AUTOSAR XML (schema 4-2-2)
package /UAES/ASW
  swc implementation Implementation: programming-language=C, sw-version=1.63.1, used-code-generator=Embedded Coder 7.1 (R2018b) 24-May-2018, vendor-id=0, behavior=InternalBehavior
    code-descriptors:
      code Code
        artifact-descriptors:
          short-label=SlpWkpReq_Ctrl_c, category=SWSRC
          short-label=APP_CFG_h, category=SWHDR
          short-label=ModeM_h, category=SWHDR
          short-label=SlpWkpReq_Ctrl_h, category=SWHDR
          short-label=rtwtypes_h, category=SWHDR
    resource consumption RsrcCons_SlpWkpReq_Ctrl
package /UAES/ASW/SwComponentTypes
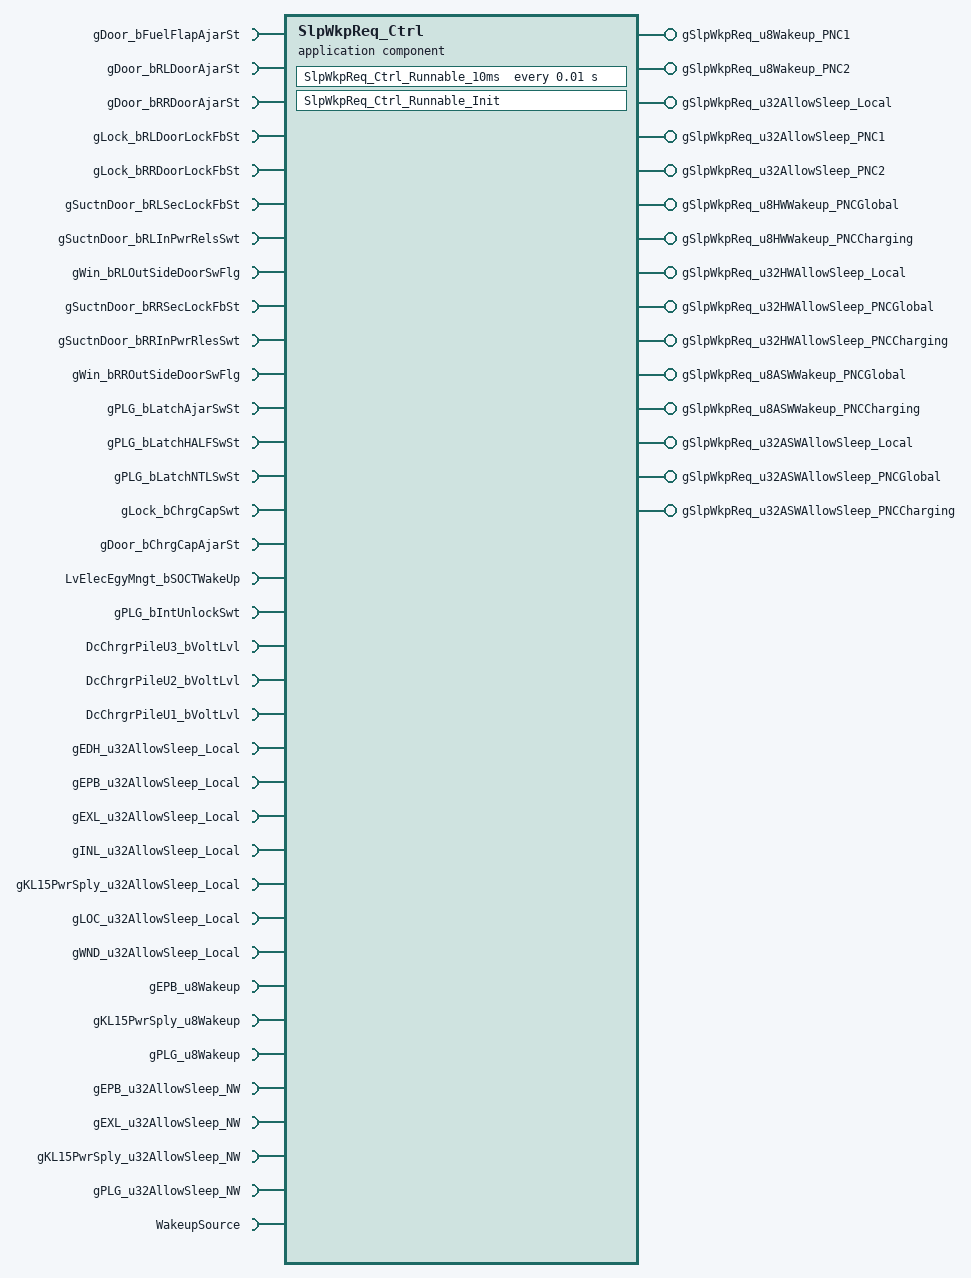
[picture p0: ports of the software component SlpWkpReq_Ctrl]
  application sw component type SlpWkpReq_Ctrl
    35 x require port:
      gDoor_bFuelFlapAjarSt: nonqueued-receiver-com-spec{data-element=gDoor_bFuelFlapAjarSt/Val, init-value=0}, required-interface=gDoor_bFuelFlapAjarSt
      gDoor_bRLDoorAjarSt: nonqueued-receiver-com-spec{data-element=gDoor_bRLDoorAjarSt/Val, init-value=0}, required-interface=gDoor_bRLDoorAjarSt
      gDoor_bRRDoorAjarSt: nonqueued-receiver-com-spec{data-element=gDoor_bRRDoorAjarSt/Val, init-value=0}, required-interface=gDoor_bRRDoorAjarSt
      gLock_bRLDoorLockFbSt: nonqueued-receiver-com-spec{data-element=gLock_bRLDoorLockFbSt/Val, init-value=0}, required-interface=gLock_bRLDoorLockFbSt
      gLock_bRRDoorLockFbSt: nonqueued-receiver-com-spec{data-element=gLock_bRRDoorLockFbSt/Val, init-value=0}, required-interface=gLock_bRRDoorLockFbSt
      gSuctnDoor_bRLSecLockFbSt: nonqueued-receiver-com-spec{data-element=gSuctnDoor_bRLSecLockFbSt/Val, init-value=0}, required-interface=gSuctnDoor_bRLSecLockFbSt
      gSuctnDoor_bRLInPwrRelsSwt: nonqueued-receiver-com-spec{data-element=gSuctnDoor_bRLInPwrRelsSwt/Val, init-value=0}, required-interface=gSuctnDoor_bRLInPwrRelsSwt
      gWin_bRLOutSideDoorSwFlg: nonqueued-receiver-com-spec{data-element=gWin_bRLOutSideDoorSwFlg/Val, init-value=0}, required-interface=gWin_bRLOutSideDoorSwFlg
      gSuctnDoor_bRRSecLockFbSt: nonqueued-receiver-com-spec{data-element=gSuctnDoor_bRRSecLockFbSt/Val, init-value=0}, required-interface=gSuctnDoor_bRRSecLockFbSt
      gSuctnDoor_bRRInPwrRlesSwt: nonqueued-receiver-com-spec{data-element=gSuctnDoor_bRRInPwrRlesSwt/Val, init-value=0}, required-interface=gSuctnDoor_bRRInPwrRlesSwt
      gWin_bRROutSideDoorSwFlg: nonqueued-receiver-com-spec{data-element=gWin_bRROutSideDoorSwFlg/Val, init-value=0}, required-interface=gWin_bRROutSideDoorSwFlg
      gPLG_bLatchAjarSwSt: nonqueued-receiver-com-spec{data-element=gPLG_bLatchAjarSwSt/Val, init-value=0}, required-interface=gPLG_bLatchAjarSwSt
      gPLG_bLatchHALFSwSt: nonqueued-receiver-com-spec{data-element=gPLG_bLatchHALFSwSt/Val, init-value=0}, required-interface=gPLG_bLatchHALFSwSt
      gPLG_bLatchNTLSwSt: nonqueued-receiver-com-spec{data-element=gPLG_bLatchNTLSwSt/Val, init-value=0}, required-interface=gPLG_bLatchNTLSwSt
      gLock_bChrgCapSwt: nonqueued-receiver-com-spec{data-element=gLock_bChrgCapSwt/Val, init-value=0}, required-interface=gLock_bChrgCapSwt
      gDoor_bChrgCapAjarSt: nonqueued-receiver-com-spec{data-element=gDoor_bChrgCapAjarSt/Val, init-value=0}, required-interface=gDoor_bChrgCapAjarSt
      LvElecEgyMngt_bSOCTWakeUp: nonqueued-receiver-com-spec{data-element=LvElecEgyMngt_bSOCTWakeUp/Val, init-value=0}, required-interface=LvElecEgyMngt_bSOCTWakeUp
      gPLG_bIntUnlockSwt: nonqueued-receiver-com-spec{data-element=gPLG_bIntUnlockSwt/Val, init-value=0}, required-interface=gPLG_bIntUnlockSwt
      DcChrgrPileU3_bVoltLvl: nonqueued-receiver-com-spec{data-element=DcChrgrPileU3_bVoltLvl/Val, init-value=0}, required-interface=DcChrgrPileU3_bVoltLvl
      DcChrgrPileU2_bVoltLvl: nonqueued-receiver-com-spec{data-element=DcChrgrPileU2_bVoltLvl/Val, init-value=0}, required-interface=DcChrgrPileU2_bVoltLvl
      DcChrgrPileU1_bVoltLvl: nonqueued-receiver-com-spec{data-element=DcChrgrPileU1_bVoltLvl/Val, init-value=0}, required-interface=DcChrgrPileU1_bVoltLvl
      gEDH_u32AllowSleep_Local: nonqueued-receiver-com-spec{data-element=gEDH_u32AllowSleep_Local/Val, init-value=0}, required-interface=gEDH_u32AllowSleep_Local
      gEPB_u32AllowSleep_Local: nonqueued-receiver-com-spec{data-element=gEPB_u32AllowSleep_Local/Val, init-value=0}, required-interface=gEPB_u32AllowSleep_Local
      gEXL_u32AllowSleep_Local: nonqueued-receiver-com-spec{data-element=gEXL_u32AllowSleep_Local/Val, init-value=0}, required-interface=gEXL_u32AllowSleep_Local
      gINL_u32AllowSleep_Local: nonqueued-receiver-com-spec{data-element=gINL_u32AllowSleep_Local/Val, init-value=0}, required-interface=gINL_u32AllowSleep_Local
      gKL15PwrSply_u32AllowSleep_Local: nonqueued-receiver-com-spec{data-element=gKL15PwrSply_u32AllowSleep_Local/Val, init-value=0}, required-interface=gKL15PwrSply_u32AllowSleep_Local
      gLOC_u32AllowSleep_Local: nonqueued-receiver-com-spec{data-element=gLOC_u32AllowSleep_Local/Val, init-value=0}, required-interface=gLOC_u32AllowSleep_Local
      gWND_u32AllowSleep_Local: nonqueued-receiver-com-spec{data-element=gWND_u32AllowSleep_Local/Val, init-value=0}, required-interface=gWND_u32AllowSleep_Local
      gEPB_u8Wakeup: nonqueued-receiver-com-spec{data-element=gEPB_u8Wakeup/Val, init-value=0}, required-interface=gEPB_u8Wakeup
      gKL15PwrSply_u8Wakeup: nonqueued-receiver-com-spec{data-element=gKL15PwrSply_u8Wakeup/Val, init-value=0}, required-interface=gKL15PwrSply_u8Wakeup
      gPLG_u8Wakeup: nonqueued-receiver-com-spec{data-element=gPLG_u8Wakeup/Val, init-value=0}, required-interface=gPLG_u8Wakeup
      gEPB_u32AllowSleep_NW: nonqueued-receiver-com-spec{data-element=gEPB_u32AllowSleep_NW/Val, init-value=0}, required-interface=gEPB_u32AllowSleep_NW
      gEXL_u32AllowSleep_NW: nonqueued-receiver-com-spec{data-element=gEXL_u32AllowSleep_NW/Val, init-value=0}, required-interface=gEXL_u32AllowSleep_NW
      gKL15PwrSply_u32AllowSleep_NW: nonqueued-receiver-com-spec{data-element=gKL15PwrSply_u32AllowSleep_NW/Val, init-value=0}, required-interface=gKL15PwrSply_u32AllowSleep_NW
      gPLG_u32AllowSleep_NW: nonqueued-receiver-com-spec{data-element=gPLG_u32AllowSleep_NW/Val, init-value=0}, required-interface=gPLG_u32AllowSleep_NW
    15 x provide port:
      gSlpWkpReq_u8Wakeup_PNC1: nonqueued-sender-com-spec{data-element=gSlpWkpReq_u8Wakeup_PNC1/Val, init-value=0}, provided-interface=gSlpWkpReq_u8Wakeup_PNC1
      gSlpWkpReq_u8Wakeup_PNC2: nonqueued-sender-com-spec{data-element=gSlpWkpReq_u8Wakeup_PNC2/Val, init-value=0}, provided-interface=gSlpWkpReq_u8Wakeup_PNC2
      gSlpWkpReq_u32AllowSleep_Local: nonqueued-sender-com-spec{data-element=gSlpWkpReq_u32AllowSleep_Local/Val, init-value=0}, provided-interface=gSlpWkpReq_u32AllowSleep_Local
      gSlpWkpReq_u32AllowSleep_PNC1: nonqueued-sender-com-spec{data-element=gSlpWkpReq_u32AllowSleep_PNC1/Val, init-value=0}, provided-interface=gSlpWkpReq_u32AllowSleep_PNC1
      gSlpWkpReq_u32AllowSleep_PNC2: nonqueued-sender-com-spec{data-element=gSlpWkpReq_u32AllowSleep_PNC2/Val, init-value=0}, provided-interface=gSlpWkpReq_u32AllowSleep_PNC2
      gSlpWkpReq_u8HWWakeup_PNCGlobal: nonqueued-sender-com-spec{data-element=gSlpWkpReq_u8HWWakeup_PNCGlobal/Val, init-value=0}, provided-interface=gSlpWkpReq_u8HWWakeup_PNCGlobal
      gSlpWkpReq_u8HWWakeup_PNCCharging: nonqueued-sender-com-spec{data-element=gSlpWkpReq_u8HWWakeup_PNCCharging/Val, init-value=0}, provided-interface=gSlpWkpReq_u8HWWakeup_PNCCharging
      gSlpWkpReq_u32HWAllowSleep_Local: nonqueued-sender-com-spec{data-element=gSlpWkpReq_u32HWAllowSleep_Local/Val, init-value=[0, 0]}, provided-interface=gSlpWkpReq_u32HWAllowSleep_Local
      gSlpWkpReq_u32HWAllowSleep_PNCGlobal: nonqueued-sender-com-spec{data-element=gSlpWkpReq_u32HWAllowSleep_PNCGlobal/Val, init-value=[0, 0]}, provided-interface=gSlpWkpReq_u32HWAllowSleep_PNCGlobal
      gSlpWkpReq_u32HWAllowSleep_PNCCharging: nonqueued-sender-com-spec{data-element=gSlpWkpReq_u32HWAllowSleep_PNCCharging/Val, init-value=[0, 0]}, provided-interface=gSlpWkpReq_u32HWAllowSleep_PNCCharging
      gSlpWkpReq_u8ASWWakeup_PNCGlobal: nonqueued-sender-com-spec{data-element=gSlpWkpReq_u8ASWWakeup_PNCGlobal/Val, init-value=0}, provided-interface=gSlpWkpReq_u8ASWWakeup_PNCGlobal
      gSlpWkpReq_u8ASWWakeup_PNCCharging: nonqueued-sender-com-spec{data-element=gSlpWkpReq_u8ASWWakeup_PNCCharging/Val, init-value=0}, provided-interface=gSlpWkpReq_u8ASWWakeup_PNCCharging
      gSlpWkpReq_u32ASWAllowSleep_Local: nonqueued-sender-com-spec{data-element=gSlpWkpReq_u32ASWAllowSleep_Local/Val, init-value=0}, provided-interface=gSlpWkpReq_u32ASWAllowSleep_Local
      gSlpWkpReq_u32ASWAllowSleep_PNCGlobal: nonqueued-sender-com-spec{data-element=gSlpWkpReq_u32ASWAllowSleep_PNCGlobal/Val, init-value=0}, provided-interface=gSlpWkpReq_u32ASWAllowSleep_PNCGlobal
      gSlpWkpReq_u32ASWAllowSleep_PNCCharging: nonqueued-sender-com-spec{data-element=gSlpWkpReq_u32ASWAllowSleep_PNCCharging/Val, init-value=0}, provided-interface=gSlpWkpReq_u32ASWAllowSleep_PNCCharging
    require port WakeupSource: required-interface=WakeupSource
    behavior InternalBehavior: handle-termination-and-restart=NO-SUPPORT
      init event SlpWkpReq_Ctrl_InitEvent: start-on-event=SlpWkpReq_Ctrl_Runnable_Init
      timing event TMT_SlpWkpReq_Ctrl_Runnable_10ms: start-on-event=SlpWkpReq_Ctrl_Runnable_10ms, period=0.01
      runnable SlpWkpReq_Ctrl_Runnable_Init
      runnable SlpWkpReq_Ctrl_Runnable_10ms
        data-receive-point-by-arguments:
          35 x access:
            IN_DcChrgrPileU{1..3}_bVoltLvl_Val: accessed-variable=DcChrgrPileU{1..3}_bVoltLvl.Val
            IN_LvElecEgyMngt_bSOCTWakeUp_Val: accessed-variable=LvElecEgyMngt_bSOCTWakeUp.Val
            IN_gDoor_bChrgCapAjarSt_Val: accessed-variable=gDoor_bChrgCapAjarSt.Val
            IN_gDoor_bFuelFlapAjarSt_Val: accessed-variable=gDoor_bFuelFlapAjarSt.Val
            IN_gDoor_bRLDoorAjarSt_Val: accessed-variable=gDoor_bRLDoorAjarSt.Val
            IN_gDoor_bRRDoorAjarSt_Val: accessed-variable=gDoor_bRRDoorAjarSt.Val
            IN_gEDH_u32AllowSleep_Local_Val: accessed-variable=gEDH_u32AllowSleep_Local.Val
            IN_gEPB_u32AllowSleep_Local_Val: accessed-variable=gEPB_u32AllowSleep_Local.Val
            IN_gEPB_u32AllowSleep_NW_Val: accessed-variable=gEPB_u32AllowSleep_NW.Val
            IN_gEPB_u8Wakeup_Val: accessed-variable=gEPB_u8Wakeup.Val
            IN_gEXL_u32AllowSleep_Local_Val: accessed-variable=gEXL_u32AllowSleep_Local.Val
            IN_gEXL_u32AllowSleep_NW_Val: accessed-variable=gEXL_u32AllowSleep_NW.Val
            IN_gINL_u32AllowSleep_Local_Val: accessed-variable=gINL_u32AllowSleep_Local.Val
            IN_gKL15PwrSply_u32AllowSleep_Local_Val: accessed-variable=gKL15PwrSply_u32AllowSleep_Local.Val
            IN_gKL15PwrSply_u32AllowSleep_NW_Val: accessed-variable=gKL15PwrSply_u32AllowSleep_NW.Val
            IN_gKL15PwrSply_u8Wakeup_Val: accessed-variable=gKL15PwrSply_u8Wakeup.Val
            IN_gLOC_u32AllowSleep_Local_Val: accessed-variable=gLOC_u32AllowSleep_Local.Val
            IN_gLock_bChrgCapSwt_Val: accessed-variable=gLock_bChrgCapSwt.Val
            IN_gLock_bRLDoorLockFbSt_Val: accessed-variable=gLock_bRLDoorLockFbSt.Val
            IN_gLock_bRRDoorLockFbSt_Val: accessed-variable=gLock_bRRDoorLockFbSt.Val
            IN_gPLG_bIntUnlockSwt_Val: accessed-variable=gPLG_bIntUnlockSwt.Val
            IN_gPLG_bLatchAjarSwSt_Val: accessed-variable=gPLG_bLatchAjarSwSt.Val
            IN_gPLG_bLatchHALFSwSt_Val: accessed-variable=gPLG_bLatchHALFSwSt.Val
            IN_gPLG_bLatchNTLSwSt_Val: accessed-variable=gPLG_bLatchNTLSwSt.Val
            IN_gPLG_u32AllowSleep_NW_Val: accessed-variable=gPLG_u32AllowSleep_NW.Val
            IN_gPLG_u8Wakeup_Val: accessed-variable=gPLG_u8Wakeup.Val
            IN_gSuctnDoor_bRLInPwrRelsSwt_Val: accessed-variable=gSuctnDoor_bRLInPwrRelsSwt.Val
            IN_gSuctnDoor_bRLSecLockFbSt_Val: accessed-variable=gSuctnDoor_bRLSecLockFbSt.Val
            IN_gSuctnDoor_bRRInPwrRlesSwt_Val: accessed-variable=gSuctnDoor_bRRInPwrRlesSwt.Val
            IN_gSuctnDoor_bRRSecLockFbSt_Val: accessed-variable=gSuctnDoor_bRRSecLockFbSt.Val
            IN_gWND_u32AllowSleep_Local_Val: accessed-variable=gWND_u32AllowSleep_Local.Val
            IN_gWin_bRLOutSideDoorSwFlg_Val: accessed-variable=gWin_bRLOutSideDoorSwFlg.Val
            IN_gWin_bRROutSideDoorSwFlg_Val: accessed-variable=gWin_bRROutSideDoorSwFlg.Val
        data-send-points:
          15 x access:
            OUT_gSlpWkpReq_u8Wakeup_PNC1_Val: accessed-variable=gSlpWkpReq_u8Wakeup_PNC1.Val
            OUT_gSlpWkpReq_u8Wakeup_PNC2_Val: accessed-variable=gSlpWkpReq_u8Wakeup_PNC2.Val
            OUT_gSlpWkpReq_u32AllowSleep_Local_Val: accessed-variable=gSlpWkpReq_u32AllowSleep_Local.Val
            OUT_gSlpWkpReq_u32AllowSleep_PNC1_Val: accessed-variable=gSlpWkpReq_u32AllowSleep_PNC1.Val
            OUT_gSlpWkpReq_u32AllowSleep_PNC2_Val: accessed-variable=gSlpWkpReq_u32AllowSleep_PNC2.Val
            OUT_gSlpWkpReq_u8HWWakeup_PNCGlobal_Val: accessed-variable=gSlpWkpReq_u8HWWakeup_PNCGlobal.Val
            OUT_gSlpWkpReq_u8HWWakeup_PNCCharging_Val: accessed-variable=gSlpWkpReq_u8HWWakeup_PNCCharging.Val
            OUT_gSlpWkpReq_u32HWAllowSleep_Local_Val: accessed-variable=gSlpWkpReq_u32HWAllowSleep_Local.Val
            OUT_gSlpWkpReq_u32HWAllowSleep_PNCGlobal_Val: accessed-variable=gSlpWkpReq_u32HWAllowSleep_PNCGlobal.Val
            OUT_gSlpWkpReq_u32HWAllowSleep_PNCCharging_Val: accessed-variable=gSlpWkpReq_u32HWAllowSleep_PNCCharging.Val
            OUT_gSlpWkpReq_u8ASWWakeup_PNCGlobal_Val: accessed-variable=gSlpWkpReq_u8ASWWakeup_PNCGlobal.Val
            OUT_gSlpWkpReq_u8ASWWakeup_PNCCharging_Val: accessed-variable=gSlpWkpReq_u8ASWWakeup_PNCCharging.Val
            OUT_gSlpWkpReq_u32ASWAllowSleep_Local_Val: accessed-variable=gSlpWkpReq_u32ASWAllowSleep_Local.Val
            OUT_gSlpWkpReq_u32ASWAllowSleep_PNCGlobal_Val: accessed-variable=gSlpWkpReq_u32ASWAllowSleep_PNCGlobal.Val
            OUT_gSlpWkpReq_u32ASWAllowSleep_PNCCharging_Val: accessed-variable=gSlpWkpReq_u32ASWAllowSleep_PNCCharging.Val
        sync call SC_WakeupSource_Operation: operation=WakeupSource.Operation, timeout=1.0E-06
package /UAES/ASW/PortInterfaces
  50 x sender receiver interface:
    gDoor_bFuelFlapAjarSt
      data Val: category=VALUE, sw-calibration-access=READ-ONLY, type=boolean
    gDoor_bRLDoorAjarSt
      data Val: category=VALUE, sw-calibration-access=READ-ONLY, type=boolean
    gDoor_bRRDoorAjarSt
      data Val: category=VALUE, sw-calibration-access=READ-ONLY, type=boolean
    gLock_bRLDoorLockFbSt
      data Val: category=VALUE, sw-calibration-access=READ-ONLY, type=boolean
    gLock_bRRDoorLockFbSt
      data Val: category=VALUE, sw-calibration-access=READ-ONLY, type=boolean
    gSuctnDoor_bRLSecLockFbSt
      data Val: category=VALUE, sw-calibration-access=READ-ONLY, type=boolean
    gSuctnDoor_bRLInPwrRelsSwt
      data Val: category=VALUE, sw-calibration-access=READ-ONLY, type=boolean
    gWin_bRLOutSideDoorSwFlg
      data Val: category=VALUE, sw-calibration-access=READ-ONLY, type=boolean
    gSuctnDoor_bRRSecLockFbSt
      data Val: category=VALUE, sw-calibration-access=READ-ONLY, type=boolean
    gSuctnDoor_bRRInPwrRlesSwt
      data Val: category=VALUE, sw-calibration-access=READ-ONLY, type=boolean
    gWin_bRROutSideDoorSwFlg
      data Val: category=VALUE, sw-calibration-access=READ-ONLY, type=boolean
    gPLG_bLatchAjarSwSt
      data Val: category=VALUE, sw-calibration-access=READ-ONLY, type=boolean
    gPLG_bLatchHALFSwSt
      data Val: category=VALUE, sw-calibration-access=READ-ONLY, type=boolean
    gPLG_bLatchNTLSwSt
      data Val: category=VALUE, sw-calibration-access=READ-ONLY, type=boolean
    gLock_bChrgCapSwt
      data Val: category=VALUE, sw-calibration-access=READ-ONLY, type=boolean
    gDoor_bChrgCapAjarSt
      data Val: category=VALUE, sw-calibration-access=READ-ONLY, type=boolean
    LvElecEgyMngt_bSOCTWakeUp
      data Val: category=VALUE, sw-calibration-access=READ-ONLY, type=boolean
    gPLG_bIntUnlockSwt
      data Val: category=VALUE, sw-calibration-access=READ-ONLY, type=boolean
    DcChrgrPileU3_bVoltLvl
      data Val: category=VALUE, sw-calibration-access=READ-ONLY, type=boolean
    DcChrgrPileU2_bVoltLvl
      data Val: category=VALUE, sw-calibration-access=READ-ONLY, type=boolean
    DcChrgrPileU1_bVoltLvl
      data Val: category=VALUE, sw-calibration-access=READ-ONLY, type=boolean
    gEDH_u32AllowSleep_Local
      data Val: category=VALUE, sw-calibration-access=READ-ONLY, type=uint32
    gEPB_u32AllowSleep_Local
      data Val: category=VALUE, sw-calibration-access=READ-ONLY, type=uint32
    gEXL_u32AllowSleep_Local
      data Val: category=VALUE, sw-calibration-access=READ-ONLY, type=uint32
    gINL_u32AllowSleep_Local
      data Val: category=VALUE, sw-calibration-access=READ-ONLY, type=uint32
    gKL15PwrSply_u32AllowSleep_Local
      data Val: category=VALUE, sw-calibration-access=READ-ONLY, type=uint32
    gLOC_u32AllowSleep_Local
      data Val: category=VALUE, sw-calibration-access=READ-ONLY, type=uint32
    gWND_u32AllowSleep_Local
      data Val: category=VALUE, sw-calibration-access=READ-ONLY, type=uint32
    gEPB_u8Wakeup
      data Val: category=VALUE, sw-calibration-access=READ-ONLY, type=uint8
    gKL15PwrSply_u8Wakeup
      data Val: category=VALUE, sw-calibration-access=READ-ONLY, type=uint8
    gPLG_u8Wakeup
      data Val: category=VALUE, sw-calibration-access=READ-ONLY, type=uint8
    gEPB_u32AllowSleep_NW
      data Val: category=VALUE, sw-calibration-access=READ-ONLY, type=uint32
    gEXL_u32AllowSleep_NW
      data Val: category=VALUE, sw-calibration-access=READ-ONLY, type=uint32
    gKL15PwrSply_u32AllowSleep_NW
      data Val: category=VALUE, sw-calibration-access=READ-ONLY, type=uint32
    gPLG_u32AllowSleep_NW
      data Val: category=VALUE, sw-calibration-access=READ-ONLY, type=uint32
    gSlpWkpReq_u8Wakeup_PNC1
      data Val: category=VALUE, sw-calibration-access=READ-ONLY, type=uint8
    gSlpWkpReq_u8Wakeup_PNC2
      data Val: category=VALUE, sw-calibration-access=READ-ONLY, type=uint8
    gSlpWkpReq_u32AllowSleep_Local
      data Val: category=VALUE, sw-calibration-access=READ-ONLY, type=uint32
    gSlpWkpReq_u32AllowSleep_PNC1
      data Val: category=VALUE, sw-calibration-access=READ-ONLY, type=uint32
    gSlpWkpReq_u32AllowSleep_PNC2
      data Val: category=VALUE, sw-calibration-access=READ-ONLY, type=uint32
    gSlpWkpReq_u8HWWakeup_PNCGlobal
      data Val: category=VALUE, sw-calibration-access=READ-ONLY, type=uint8
    gSlpWkpReq_u8HWWakeup_PNCCharging
      data Val: category=VALUE, sw-calibration-access=READ-ONLY, type=uint8
    gSlpWkpReq_u32HWAllowSleep_Local
      data Val: category=ARRAY, sw-calibration-access=READ-ONLY, type=rt_Array_uint32_2
    gSlpWkpReq_u32HWAllowSleep_PNCGlobal
      data Val: category=ARRAY, sw-calibration-access=READ-ONLY, type=rt_Array_uint32_2
    gSlpWkpReq_u32HWAllowSleep_PNCCharging
      data Val: category=ARRAY, sw-calibration-access=READ-ONLY, type=rt_Array_uint32_2
    gSlpWkpReq_u8ASWWakeup_PNCGlobal
      data Val: category=VALUE, sw-calibration-access=READ-ONLY, type=uint8
    gSlpWkpReq_u8ASWWakeup_PNCCharging
      data Val: category=VALUE, sw-calibration-access=READ-ONLY, type=uint8
    gSlpWkpReq_u32ASWAllowSleep_Local
      data Val: category=VALUE, sw-calibration-access=READ-ONLY, type=uint32
    gSlpWkpReq_u32ASWAllowSleep_PNCGlobal
      data Val: category=VALUE, sw-calibration-access=READ-ONLY, type=uint32
    gSlpWkpReq_u32ASWAllowSleep_PNCCharging
      data Val: category=VALUE, sw-calibration-access=READ-ONLY, type=uint32
  client server interface WakeupSource
    operation Operation
      arg u8WkSrcEvent: category=VALUE, sw-calibration-access=READ-ONLY, type=uint8, direction=OUT
      arg u16AdcWkSrcChn: category=VALUE, sw-calibration-access=READ-ONLY, type=uint16, direction=OUT
      arg u32DiWkSrcChn: category=VALUE, sw-calibration-access=READ-ONLY, type=uint32, direction=OUT
package /UAES/ASW/ImplementationDataTypes
  impl type rt_Array_uint32_2: category=ARRAY
    element rt_Array_uint32_2: array-size=2, array-size-semantics=FIXED-SIZE, implementation-data-type=uint32
